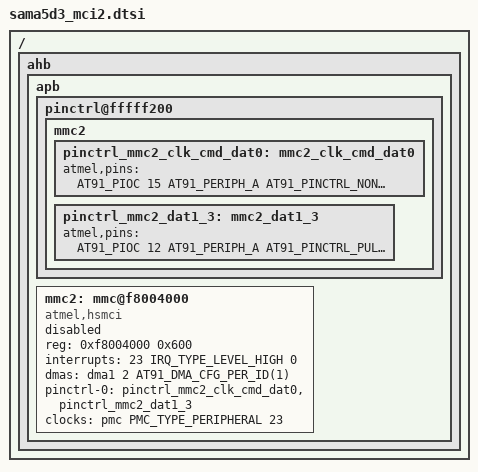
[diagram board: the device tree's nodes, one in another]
#include <dt-bindings/pinctrl/at91.h>
#include <dt-bindings/interrupt-controller/irq.h>
#include <dt-bindings/clock/at91.h>
/ {
	ahb {
		apb {
			pinctrl@fffff200 {
				mmc2 {
					pinctrl_mmc2_clk_cmd_dat0: mmc2_clk_cmd_dat0 {
						atmel,pins =
							<AT91_PIOC 15 AT91_PERIPH_A AT91_PINCTRL_NONE	 
							 AT91_PIOC 10 AT91_PERIPH_A AT91_PINCTRL_PULL_UP	 
							 AT91_PIOC 11 AT91_PERIPH_A AT91_PINCTRL_PULL_UP>;	 
					};
					pinctrl_mmc2_dat1_3: mmc2_dat1_3 {
						atmel,pins =
							<AT91_PIOC 12 AT91_PERIPH_A AT91_PINCTRL_PULL_UP	 
							 AT91_PIOC 13 AT91_PERIPH_A AT91_PINCTRL_PULL_UP	 
							 AT91_PIOC 14 AT91_PERIPH_A AT91_PINCTRL_PULL_UP>;	 
					};
				};
			};
			mmc2: mmc@f8004000 {
				compatible = "atmel,hsmci";
				reg = <0xf8004000 0x600>;
				interrupts = <23 IRQ_TYPE_LEVEL_HIGH 0>;
				dmas = <&dma1 2 AT91_DMA_CFG_PER_ID(1)>;
				dma-names = "rxtx";
				pinctrl-names = "default";
				pinctrl-0 = <&pinctrl_mmc2_clk_cmd_dat0 &pinctrl_mmc2_dat1_3>;
				clocks = <&pmc PMC_TYPE_PERIPHERAL 23>;
				clock-names = "mci_clk";
				status = "disabled";
				#address-cells = <1>;
				#size-cells = <0>;
			};
		};
	};
};
